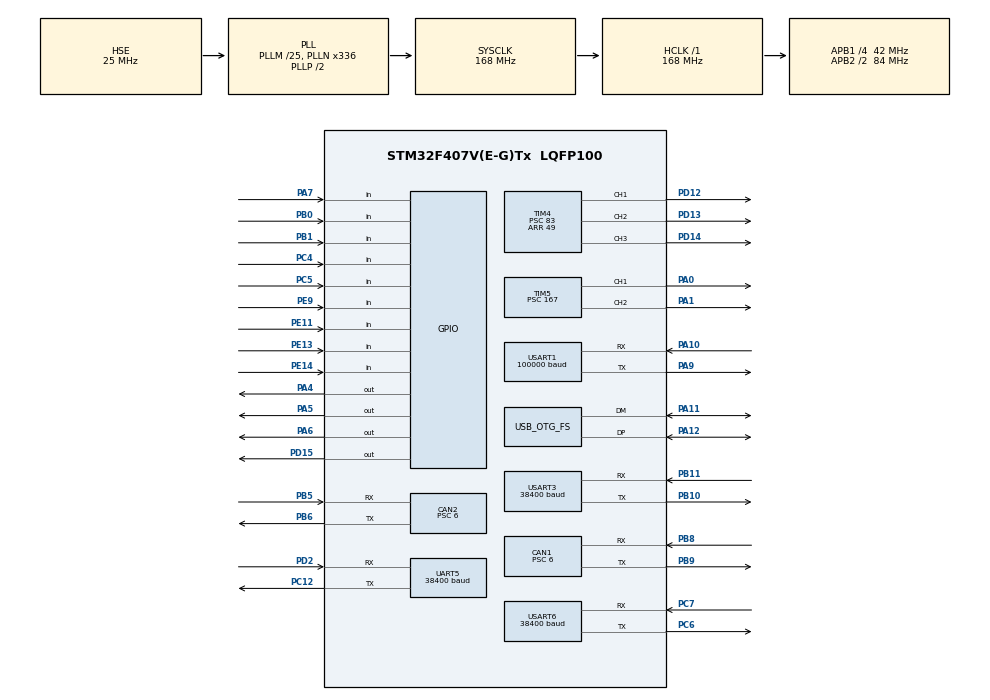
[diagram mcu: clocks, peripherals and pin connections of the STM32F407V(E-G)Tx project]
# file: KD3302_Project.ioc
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CAN1.BS1=CAN_BS1_3TQ
CAN1.BS2=CAN_BS2_3TQ
CAN1.CalculateBaudRate=1000000
CAN1.CalculateTimeBit=1000
CAN1.CalculateTimeQuantum=142.85714285714286
CAN1.Prescaler=6
CAN2.BS1=CAN_BS1_3TQ
CAN2.BS2=CAN_BS2_3TQ
CAN2.CalculateBaudRate=1000000
CAN2.CalculateTimeBit=1000
CAN2.CalculateTimeQuantum=142.85714285714286
CAN2.Prescaler=6
Dma.Request0=USART3_RX
Dma.Request1=USART6_RX
Dma.Request2=USART6_TX
Dma.Request3=USART3_TX
Dma.Request4=USART1_RX
Dma.Request5=UART5_RX
Dma.UART5_RX.5.Direction=DMA_PERIPH_TO_MEMORY
Dma.UART5_RX.5.FIFOMode=DMA_FIFOMODE_DISABLE
Dma.UART5_RX.5.Instance=DMA1_Stream0
Dma.UART5_RX.5.MemDataAlignment=DMA_MDATAALIGN_BYTE
Dma.UART5_RX.5.MemInc=DMA_MINC_ENABLE
Dma.UART5_RX.5.Mode=DMA_NORMAL
Dma.UART5_RX.5.PeriphDataAlignment=DMA_PDATAALIGN_BYTE
Dma.UART5_RX.5.PeriphInc=DMA_PINC_DISABLE
Dma.UART5_RX.5.Priority=DMA_PRIORITY_LOW
Dma.USART1_RX.4.Direction=DMA_PERIPH_TO_MEMORY
Dma.USART1_RX.4.FIFOMode=DMA_FIFOMODE_DISABLE
Dma.USART1_RX.4.Instance=DMA2_Stream2
Dma.USART1_RX.4.MemDataAlignment=DMA_MDATAALIGN_BYTE
Dma.USART1_RX.4.MemInc=DMA_MINC_ENABLE
Dma.USART1_RX.4.Mode=DMA_NORMAL
Dma.USART1_RX.4.PeriphDataAlignment=DMA_PDATAALIGN_BYTE
Dma.USART1_RX.4.PeriphInc=DMA_PINC_DISABLE
Dma.USART1_RX.4.Priority=DMA_PRIORITY_LOW
Dma.USART3_RX.0.Direction=DMA_PERIPH_TO_MEMORY
Dma.USART3_RX.0.FIFOMode=DMA_FIFOMODE_DISABLE
Dma.USART3_RX.0.Instance=DMA1_Stream1
Dma.USART3_RX.0.MemDataAlignment=DMA_MDATAALIGN_BYTE
Dma.USART3_RX.0.MemInc=DMA_MINC_ENABLE
Dma.USART3_RX.0.Mode=DMA_NORMAL
Dma.USART3_RX.0.PeriphDataAlignment=DMA_PDATAALIGN_BYTE
Dma.USART3_RX.0.PeriphInc=DMA_PINC_DISABLE
Dma.USART3_RX.0.Priority=DMA_PRIORITY_LOW
Dma.USART3_TX.3.Direction=DMA_MEMORY_TO_PERIPH
Dma.USART3_TX.3.FIFOMode=DMA_FIFOMODE_DISABLE
Dma.USART3_TX.3.Instance=DMA1_Stream3
Dma.USART3_TX.3.MemDataAlignment=DMA_MDATAALIGN_BYTE
Dma.USART3_TX.3.MemInc=DMA_MINC_ENABLE
Dma.USART3_TX.3.Mode=DMA_NORMAL
Dma.USART3_TX.3.PeriphDataAlignment=DMA_PDATAALIGN_BYTE
Dma.USART3_TX.3.PeriphInc=DMA_PINC_DISABLE
Dma.USART3_TX.3.Priority=DMA_PRIORITY_LOW
Dma.USART6_RX.1.Direction=DMA_PERIPH_TO_MEMORY
Dma.USART6_RX.1.FIFOMode=DMA_FIFOMODE_DISABLE
Dma.USART6_RX.1.Instance=DMA2_Stream1
Dma.USART6_RX.1.MemDataAlignment=DMA_MDATAALIGN_BYTE
Dma.USART6_RX.1.MemInc=DMA_MINC_ENABLE
Dma.USART6_RX.1.Mode=DMA_NORMAL
Dma.USART6_RX.1.PeriphDataAlignment=DMA_PDATAALIGN_BYTE
Dma.USART6_RX.1.PeriphInc=DMA_PINC_DISABLE
Dma.USART6_RX.1.Priority=DMA_PRIORITY_LOW
Dma.USART6_TX.2.Direction=DMA_MEMORY_TO_PERIPH
Dma.USART6_TX.2.FIFOMode=DMA_FIFOMODE_DISABLE
Dma.USART6_TX.2.Instance=DMA2_Stream6
Dma.USART6_TX.2.MemDataAlignment=DMA_MDATAALIGN_BYTE
Dma.USART6_TX.2.MemInc=DMA_MINC_ENABLE
Dma.USART6_TX.2.Mode=DMA_NORMAL
Dma.USART6_TX.2.PeriphDataAlignment=DMA_PDATAALIGN_BYTE
Dma.USART6_TX.2.PeriphInc=DMA_PINC_DISABLE
Dma.USART6_TX.2.Priority=DMA_PRIORITY_LOW
FREERTOS.BinarySemaphores01=myBinarySem01,Dynamic,NULL
FREERTOS.INCLUDE_uxTaskGetStackHighWaterMark=1
FREERTOS.INCLUDE_vTaskDelayUntil=1
FREERTOS.Tasks01=defaultTask,0,128,StartDefaultTask,Default,NULL,Dynamic,NULL,NULL
Mcu.Family=STM32F4
Mcu.Name=STM32F407V(E-G)Tx
Mcu.Package=LQFP100
NVIC.CAN1_RX0_IRQn=true\:5\:0\:false\:false\:true\:true\:true\:true\:true
NVIC.CAN2_RX1_IRQn=true\:5\:0\:false\:false\:true\:true\:true\:true\:true
NVIC.DMA1_Stream0_IRQn=true\:5\:0\:false\:false\:true\:true\:false\:true\:true
NVIC.DMA1_Stream1_IRQn=true\:5\:0\:false\:false\:true\:true\:false\:true\:true
NVIC.DMA1_Stream3_IRQn=true\:5\:0\:false\:false\:true\:true\:false\:true\:true
NVIC.DMA2_Stream1_IRQn=true\:5\:0\:false\:false\:true\:true\:false\:true\:true
NVIC.DMA2_Stream2_IRQn=true\:5\:0\:false\:false\:true\:true\:false\:true\:true
NVIC.DMA2_Stream6_IRQn=true\:5\:0\:false\:false\:true\:true\:false\:true\:true
NVIC.OTG_FS_IRQn=true\:5\:0\:false\:false\:true\:true\:false\:true\:true
NVIC.PriorityGroup=NVIC_PRIORITYGROUP_4
NVIC.TIM1_UP_TIM10_IRQn=true\:5\:0\:false\:false\:true\:true\:true\:true\:true
NVIC.TIM2_IRQn=true\:5\:0\:false\:false\:true\:true\:true\:true\:true
NVIC.TIM4_IRQn=true\:5\:0\:false\:false\:true\:true\:true\:true\:true
NVIC.TIM5_IRQn=true\:5\:0\:false\:false\:true\:true\:true\:true\:true
NVIC.TIM8_BRK_TIM12_IRQn=true\:5\:0\:false\:false\:true\:true\:true\:true\:true
NVIC.TIM8_UP_TIM13_IRQn=true\:15\:0\:false\:false\:true\:false\:false\:true\:true
NVIC.TimeBase=TIM8_UP_TIM13_IRQn
NVIC.TimeBaseIP=TIM8
NVIC.UART5_IRQn=true\:5\:0\:false\:false\:true\:true\:true\:true\:true
NVIC.USART1_IRQn=true\:5\:0\:false\:false\:true\:true\:true\:true\:true
NVIC.USART3_IRQn=true\:5\:0\:false\:false\:true\:true\:true\:true\:true
NVIC.USART6_IRQn=true\:5\:0\:false\:false\:true\:true\:true\:true\:true
PA0-WKUP.Signal=S_TIM5_CH1
PA1.Signal=S_TIM5_CH2
PA10.Mode=Asynchronous
PA10.Signal=USART1_RX
PA11.Mode=Device_Only
PA11.Signal=USB_OTG_FS_DM
PA12.Mode=Device_Only
PA12.Signal=USB_OTG_FS_DP
PA13.Mode=Serial_Wire
PA13.Signal=SYS_JTMS-SWDIO
PA14.Mode=Serial_Wire
PA14.Signal=SYS_JTCK-SWCLK
PA4.Signal=GPIO_Output
PA5.Signal=GPIO_Output
PA6.Signal=GPIO_Output
PA7.Signal=GPIO_Input
PA9.Mode=Asynchronous
PA9.Signal=USART1_TX
PB0.Signal=GPIO_Input
PB1.Signal=GPIO_Input
PB10.GPIO_PuPd=GPIO_PULLUP
PB10.Mode=Asynchronous
PB10.Signal=USART3_TX
PB11.GPIO_PuPd=GPIO_PULLUP
PB11.Mode=Asynchronous
PB11.Signal=USART3_RX
PB5.Mode=CAN_Activate
PB5.Signal=CAN2_RX
PB6.Mode=CAN_Activate
PB6.Signal=CAN2_TX
PB8.Mode=CAN_Activate
PB8.Signal=CAN1_RX
PB9.Mode=CAN_Activate
PB9.Signal=CAN1_TX
PC12.GPIO_PuPd=GPIO_PULLUP
PC12.Mode=Asynchronous
PC12.Signal=UART5_TX
PC4.Signal=GPIO_Input
PC5.Signal=GPIO_Input
PC6.GPIO_PuPd=GPIO_PULLUP
PC6.Mode=Asynchronous
PC6.Signal=USART6_TX
PC7.GPIO_PuPd=GPIO_PULLUP
PC7.Mode=Asynchronous
PC7.Signal=USART6_RX
PD12.Signal=S_TIM4_CH1
PD13.Signal=S_TIM4_CH2
PD14.Signal=S_TIM4_CH3
PD15.Signal=GPIO_Output
PD2.GPIO_PuPd=GPIO_PULLUP
PD2.Mode=Asynchronous
PD2.Signal=UART5_RX
PE11.Signal=GPIO_Input
PE13.Signal=GPIO_Input
PE14.Signal=GPIO_Input
PE9.Signal=GPIO_Input
PH0-OSC_IN.Mode=HSE-External-Oscillator
PH0-OSC_IN.Signal=RCC_OSC_IN
PH1-OSC_OUT.Mode=HSE-External-Oscillator
PH1-OSC_OUT.Signal=RCC_OSC_OUT
ProjectManager.HeapSize=0x800
ProjectManager.StackSize=0x800
ProjectManager.TargetToolchain=MDK-ARM V5
RCC.48MHZClocksFreq_Value=48000000
RCC.AHBFreq_Value=168000000
RCC.APB1CLKDivider=RCC_HCLK_DIV4
RCC.APB1Freq_Value=42000000
RCC.APB1TimFreq_Value=84000000
RCC.APB2CLKDivider=RCC_HCLK_DIV2
RCC.APB2Freq_Value=84000000
RCC.APB2TimFreq_Value=168000000
RCC.CortexFreq_Value=168000000
RCC.HCLKFreq_Value=168000000
RCC.HSE_VALUE=25000000
RCC.HSI_VALUE=16000000
RCC.LSE_VALUE=32768
RCC.PLLM=25
RCC.PLLN=336
RCC.PLLQ=7
RCC.SYSCLKFreq_VALUE=168000000
RCC.SYSCLKSource=RCC_SYSCLKSOURCE_PLLCLK
RCC.VCOOutputFreq_Value=336000000
SH.S_TIM4_CH1.0=TIM4_CH1,PWM Generation1 CH1
SH.S_TIM4_CH2.0=TIM4_CH2,PWM Generation2 CH2
SH.S_TIM4_CH3.0=TIM4_CH3,PWM Generation3 CH3
SH.S_TIM5_CH1.0=TIM5_CH1,PWM Generation1 CH1
SH.S_TIM5_CH2.0=TIM5_CH2,PWM Generation2 CH2
TIM1.Period=999
TIM1.Prescaler=167
TIM12.Period=999
TIM12.Prescaler=167
TIM2.Period=999
TIM2.Prescaler=83
TIM4.Channel-PWM\ Generation1\ CH1=TIM_CHANNEL_1
TIM4.Channel-PWM\ Generation2\ CH2=TIM_CHANNEL_2
TIM4.Channel-PWM\ Generation3\ CH3=TIM_CHANNEL_3
TIM4.Period=49
TIM4.Prescaler=83
TIM5.Channel-PWM\ Generation1\ CH1=TIM_CHANNEL_1
TIM5.Channel-PWM\ Generation2\ CH2=TIM_CHANNEL_2
TIM5.Period=999
TIM5.Prescaler=167
UART5.BaudRate=38400
UART5.VirtualMode=Asynchronous
USART1.BaudRate=100000
USART1.VirtualMode=VM_ASYNC
USART3.BaudRate=38400
USART3.VirtualMode=VM_ASYNC
USART6.BaudRate=38400
USART6.VirtualMode=VM_ASYNC
USB_DEVICE.CLASS_NAME_FS=CDC
USB_DEVICE.VirtualMode-CDC_FS=Cdc
USB_DEVICE.VirtualModeFS=Cdc_FS
USB_OTG_FS.VirtualMode=Device_Only
VP_FREERTOS_VS_CMSIS_V1.Mode=CMSIS_V1
VP_SYS_VS_tim8.Mode=TIM8
VP_TIM12_VS_ClockSourceINT.Mode=Internal
VP_TIM1_VS_ClockSourceINT.Mode=Internal
VP_TIM2_VS_ClockSourceINT.Mode=Internal
VP_TIM4_VS_ClockSourceINT.Mode=Internal
VP_TIM5_VS_ClockSourceINT.Mode=Internal
VP_USB_DEVICE_VS_USB_DEVICE_CDC_FS.Mode=CDC_FS
board=custom

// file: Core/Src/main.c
/* USER CODE BEGIN Header */
/**
  ******************************************************************************
  * @file           : main.c
  * @brief          : Main program body
  ******************************************************************************
  * @attention
  *
  * Copyright (c) 2023 STMicroelectronics.
  * All rights reserved.
  *
  * This software is licensed under terms that can be found in the LICENSE file
  * in the root directory of this software component.
  * If no LICENSE file comes with this software, it is provided AS-IS.
  *
  ******************************************************************************
  */
/* USER CODE END Header */
#include "main.h"
#include "cmsis_os.h"
#include "can.h"
#include "dma.h"
#include "tim.h"
#include "usart.h"
#include "usb_device.h"
#include "gpio.h"

void SystemClock_Config(void);
void MX_FREERTOS_Init(void);

int main(void)
{

  /* MCU Configuration--------------------------------------------------------*/

  /* Reset of all peripherals, Initializes the Flash interface and the Systick. */
  HAL_Init();

  /* Configure the system clock */
  SystemClock_Config();

  /* Initialize all configured peripherals */
  MX_GPIO_Init();
  MX_DMA_Init();
  MX_CAN1_Init();
  MX_CAN2_Init();
  MX_TIM4_Init();
  MX_USART3_UART_Init();
  MX_USART6_UART_Init();
  MX_USART1_UART_Init();
  MX_TIM5_Init();
  MX_TIM1_Init();
  MX_TIM12_Init();
  MX_UART5_Init();
  MX_TIM2_Init();

  /* Call init function for freertos objects (in freertos.c) */
  MX_FREERTOS_Init();

  /* Start scheduler */
  osKernelStart();
  /* We should never get here as control is now taken by the scheduler */
  /* Infinite loop */
  while (1)
  {

  }
}

void SystemClock_Config(void)
{
  RCC_OscInitTypeDef RCC_OscInitStruct = {0};
  RCC_ClkInitTypeDef RCC_ClkInitStruct = {0};

  /** Configure the main internal regulator output voltage
  */
  __HAL_RCC_PWR_CLK_ENABLE();
  __HAL_PWR_VOLTAGESCALING_CONFIG(PWR_REGULATOR_VOLTAGE_SCALE1);

  /** Initializes the RCC Oscillators according to the specified parameters
  * in the RCC_OscInitTypeDef structure.
  */
  RCC_OscInitStruct.OscillatorType = RCC_OSCILLATORTYPE_HSE;
  RCC_OscInitStruct.HSEState = RCC_HSE_ON;
  RCC_OscInitStruct.PLL.PLLState = RCC_PLL_ON;
  RCC_OscInitStruct.PLL.PLLSource = RCC_PLLSOURCE_HSE;
  RCC_OscInitStruct.PLL.PLLM = 25;
  RCC_OscInitStruct.PLL.PLLN = 336;
  RCC_OscInitStruct.PLL.PLLP = RCC_PLLP_DIV2;
  RCC_OscInitStruct.PLL.PLLQ = 7;
  if (HAL_RCC_OscConfig(&RCC_OscInitStruct) != HAL_OK)
  {
    Error_Handler();
  }

  /** Initializes the CPU, AHB and APB buses clocks
  */
  RCC_ClkInitStruct.ClockType = RCC_CLOCKTYPE_HCLK|RCC_CLOCKTYPE_SYSCLK
                              |RCC_CLOCKTYPE_PCLK1|RCC_CLOCKTYPE_PCLK2;
  RCC_ClkInitStruct.SYSCLKSource = RCC_SYSCLKSOURCE_PLLCLK;
  RCC_ClkInitStruct.AHBCLKDivider = RCC_SYSCLK_DIV1;
  RCC_ClkInitStruct.APB1CLKDivider = RCC_HCLK_DIV4;
  RCC_ClkInitStruct.APB2CLKDivider = RCC_HCLK_DIV2;

  if (HAL_RCC_ClockConfig(&RCC_ClkInitStruct, FLASH_LATENCY_5) != HAL_OK)
  {
    Error_Handler();
  }
}

void HAL_TIM_PeriodElapsedCallback(TIM_HandleTypeDef *htim)
{
  if (htim->Instance == TIM8) {
    HAL_IncTick();
  }
}

void Error_Handler(void)
{
  __disable_irq();
  while (1)
  {
  }
}

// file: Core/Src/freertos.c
/* USER CODE BEGIN Header */
/**
  ******************************************************************************
  * File Name          : freertos.c
  * Description        : Code for freertos applications
  ******************************************************************************
  * @attention
  *
  * Copyright (c) 2023 STMicroelectronics.
  * All rights reserved.
  *
  * This software is licensed under terms that can be found in the LICENSE file
  * in the root directory of this software component.
  * If no LICENSE file comes with this software, it is provided AS-IS.
  *
  ******************************************************************************
  */
/* USER CODE END Header */

#include "FreeRTOS.h"
#include "task.h"
#include "main.h"
#include "cmsis_os.h"

/* USER CODE BEGIN Includes */
#include "Task_Init.h"
/* USER CODE END Includes */

osThreadId defaultTaskHandle;
osSemaphoreId myBinarySem01Handle;

void StartDefaultTask(void const * argument);

extern void MX_USB_DEVICE_Init(void);
void MX_FREERTOS_Init(void); /* (MISRA C 2004 rule 8.1) */

/* GetIdleTaskMemory prototype (linked to static allocation support) */
void vApplicationGetIdleTaskMemory( StaticTask_t **ppxIdleTaskTCBBuffer, StackType_t **ppxIdleTaskStackBuffer, uint32_t *pulIdleTaskStackSize );

/* USER CODE BEGIN GET_IDLE_TASK_MEMORY */
static StaticTask_t xIdleTaskTCBBuffer;
static StackType_t xIdleStack[configMINIMAL_STACK_SIZE];

void vApplicationGetIdleTaskMemory( StaticTask_t **ppxIdleTaskTCBBuffer, StackType_t **ppxIdleTaskStackBuffer, uint32_t *pulIdleTaskStackSize )
{
  *ppxIdleTaskTCBBuffer = &xIdleTaskTCBBuffer;
  *ppxIdleTaskStackBuffer = &xIdleStack[0];
  *pulIdleTaskStackSize = configMINIMAL_STACK_SIZE;
  /* place for user code */
}
/* USER CODE END GET_IDLE_TASK_MEMORY */

void MX_FREERTOS_Init(void) {

  /* Create the semaphores(s) */
  /* definition and creation of myBinarySem01 */
  osSemaphoreDef(myBinarySem01);
  myBinarySem01Handle = osSemaphoreCreate(osSemaphore(myBinarySem01), 1);

  /* Create the thread(s) */
  /* definition and creation of defaultTask */
  osThreadDef(defaultTask, StartDefaultTask, osPriorityNormal, 0, 128);
  defaultTaskHandle = osThreadCreate(osThread(defaultTask), NULL);

}

void StartDefaultTask(void const * argument)
{
  /* init code for USB_DEVICE */
  MX_USB_DEVICE_Init();
  /* USER CODE BEGIN StartDefaultTask */
  /* Infinite loop */
  for(;;)
  {
    taskENTER_CRITICAL();
    Start_Task();
    /* 出临界区 */
    taskEXIT_CRITICAL();
    /* 删除初始任务 */
    vTaskDelete(NULL);
    osDelay(1);
  }
  /* USER CODE END StartDefaultTask */
}
